AUTOSAR XML (schema 4-2-2)
package /Components
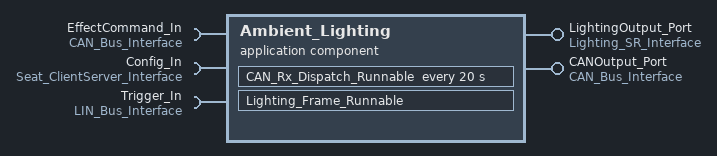
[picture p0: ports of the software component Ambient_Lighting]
  application sw component type Ambient_Lighting
    provide port LightingOutput_Port: provided-interface=Lighting_SR_Interface
    provide port CANOutput_Port: provided-interface=CAN_Bus_Interface
    require port EffectCommand_In: required-interface=CAN_Bus_Interface
    require port Config_In: required-interface=Seat_ClientServer_Interface
    require port Trigger_In: required-interface=LIN_Bus_Interface
    behavior Ambient_Lighting_InternalBehavior
      external trigger occurred event Effect_Change_Event: start-on-event=Seat_Control_Runnable
      timing event Lighting_Frame_Tick: start-on-event=CAN_Rx_Dispatch_Runnable, period=20
      runnable Lighting_Frame_Runnable: minimum-start-interval=20, symbol=Ambient_Lighting_Lighting_Frame_Runnable
        data-receive-point-by-arguments:
          access EffectCommand_Access: accessed-variable=EffectCommand_In.EffectCommand
          access Config_Access: accessed-variable=Config_In.ColorConfig
        data-send-points:
          access LightingFrame_Out: accessed-variable=LightingOutput_Port.Lighting_Frame
          access CANFrame_Out: accessed-variable=CANOutput_Port.CAN_Lighting_Frame
